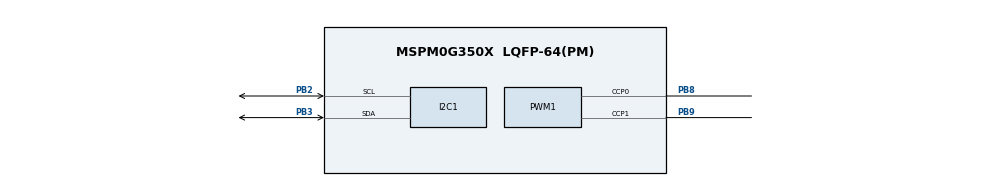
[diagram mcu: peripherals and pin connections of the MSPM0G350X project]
/**
 * @cliArgs --device "MSPM0G350X" --part "Default" --package "LQFP-64(PM)" --product "mspm0_sdk@2.05.00.05"
 * @versions {"tool":"1.24.0+4110"}
 */

/**
 * Import the modules used in this configuration.
 */
const ADC12  = scripting.addModule("/ti/driverlib/ADC12", {}, false);
const ADC121 = ADC12.addInstance();
const GPIO   = scripting.addModule("/ti/driverlib/GPIO", {}, false);
const GPIO1  = GPIO.addInstance();
const GPIO2  = GPIO.addInstance();
const GPIO3  = GPIO.addInstance();
const GPIO4  = GPIO.addInstance();
const GPIO5  = GPIO.addInstance();
const I2C    = scripting.addModule("/ti/driverlib/I2C", {}, false);
const I2C1   = I2C.addInstance();
const PWM    = scripting.addModule("/ti/driverlib/PWM", {}, false);
const PWM1   = PWM.addInstance();
const SYSCTL = scripting.addModule("/ti/driverlib/SYSCTL");
const TIMER  = scripting.addModule("/ti/driverlib/TIMER", {}, false);
const TIMER1 = TIMER.addInstance();

/**
 * Write custom configuration values to the imported modules.
 */
const divider7       = system.clockTree["PLL_PDIV"];
divider7.divideValue = 2;

const divider9       = system.clockTree["UDIV"];
divider9.divideValue = 2;

const multiplier2         = system.clockTree["PLL_QDIV"];
multiplier2.multiplyValue = 5;

const mux8       = system.clockTree["HSCLKMUX"];
mux8.inputSelect = "HSCLKMUX_SYSPLL2X";

ADC121.$name                             = "ADC1";
ADC121.repeatMode                        = true;
ADC121.sampClkDiv                        = "DL_ADC12_CLOCK_DIVIDE_8";
ADC121.adcMem0_name                      = "ADC_Channel0";
ADC121.powerDownMode                     = "DL_ADC12_POWER_DOWN_MODE_MANUAL";
ADC121.adcPin0Config.$name               = "ti_driverlib_gpio_GPIOPinGeneric4";
ADC121.adcPin0Config.hideOutputInversion = scripting.forceWrite(false);

const Board = scripting.addModule("/ti/driverlib/Board", {}, false);

GPIO1.$name                          = "GPIO_motor";
GPIO1.associatedPins.create(5);
GPIO1.associatedPins[0].$name        = "PIN_AIN1";
GPIO1.associatedPins[0].assignedPort = "PORTB";
GPIO1.associatedPins[0].assignedPin  = "6";
GPIO1.associatedPins[1].$name        = "PIN_AIN2";
GPIO1.associatedPins[1].assignedPort = "PORTB";
GPIO1.associatedPins[1].assignedPin  = "7";
GPIO1.associatedPins[2].$name        = "PIN_BIN1";
GPIO1.associatedPins[2].assignedPort = "PORTB";
GPIO1.associatedPins[2].assignedPin  = "15";
GPIO1.associatedPins[3].$name        = "PIN_BIN2";
GPIO1.associatedPins[3].assignedPort = "PORTB";
GPIO1.associatedPins[3].assignedPin  = "0";
GPIO1.associatedPins[4].$name        = "PIN_STBY";
GPIO1.associatedPins[4].assignedPort = "PORTB";
GPIO1.associatedPins[4].assignedPin  = "16";

GPIO2.$name                          = "GPIO_Encoder";
GPIO2.associatedPins.create(4);
GPIO2.associatedPins[0].$name        = "PIN_Left_E1A";
GPIO2.associatedPins[0].direction    = "INPUT";
GPIO2.associatedPins[0].assignedPort = "PORTA";
GPIO2.associatedPins[0].assignedPin  = "12";
GPIO2.associatedPins[0].interruptEn  = true;
GPIO2.associatedPins[0].polarity     = "FALL";
GPIO2.associatedPins[1].$name        = "PIN_Left_E1B";
GPIO2.associatedPins[1].direction    = "INPUT";
GPIO2.associatedPins[1].assignedPin  = "13";
GPIO2.associatedPins[1].assignedPort = "PORTA";
GPIO2.associatedPins[2].$name        = "PIN_Right_E2A";
GPIO2.associatedPins[2].direction    = "INPUT";
GPIO2.associatedPins[2].assignedPort = "PORTB";
GPIO2.associatedPins[2].assignedPin  = "12";
GPIO2.associatedPins[2].interruptEn  = true;
GPIO2.associatedPins[2].polarity     = "FALL";
GPIO2.associatedPins[3].$name        = "PIN_Right_E2B";
GPIO2.associatedPins[3].direction    = "INPUT";
GPIO2.associatedPins[3].assignedPort = "PORTB";
GPIO2.associatedPins[3].assignedPin  = "17";

GPIO3.$name                          = "GPIO_LED";
GPIO3.associatedPins[0].$name        = "PIN_LED";
GPIO3.associatedPins[0].initialValue = "SET";
GPIO3.associatedPins[0].assignedPort = "PORTA";
GPIO3.associatedPins[0].assignedPin  = "0";

GPIO4.$name                              = "GPIO_KEY";
GPIO4.associatedPins.create(8);
GPIO4.associatedPins[0].$name            = "PIN_KEY_ROW1";
GPIO4.associatedPins[0].initialValue     = "SET";
GPIO4.associatedPins[0].assignedPort     = "PORTA";
GPIO4.associatedPins[0].assignedPin      = "26";
GPIO4.associatedPins[1].$name            = "PIN_KEY_ROW2";
GPIO4.associatedPins[1].initialValue     = "SET";
GPIO4.associatedPins[1].assignedPort     = "PORTB";
GPIO4.associatedPins[1].assignedPin      = "18";
GPIO4.associatedPins[2].$name            = "PIN_KEY_ROW3";
GPIO4.associatedPins[2].initialValue     = "SET";
GPIO4.associatedPins[2].assignedPort     = "PORTB";
GPIO4.associatedPins[2].assignedPin      = "24";
GPIO4.associatedPins[3].$name            = "PIN_KEY_ROW4";
GPIO4.associatedPins[3].initialValue     = "SET";
GPIO4.associatedPins[3].assignedPort     = "PORTA";
GPIO4.associatedPins[3].assignedPin      = "24";
GPIO4.associatedPins[4].$name            = "PIN_KEY_COL1";
GPIO4.associatedPins[4].direction        = "INPUT";
GPIO4.associatedPins[4].assignedPort     = "PORTA";
GPIO4.associatedPins[4].assignedPin      = "22";
GPIO4.associatedPins[4].internalResistor = "PULL_UP";
GPIO4.associatedPins[5].$name            = "PIN_KEY_COL2";
GPIO4.associatedPins[5].direction        = "INPUT";
GPIO4.associatedPins[5].internalResistor = "PULL_UP";
GPIO4.associatedPins[5].assignedPort     = "PORTA";
GPIO4.associatedPins[5].assignedPin      = "8";
GPIO4.associatedPins[6].$name            = "PIN_KEY_COL3";
GPIO4.associatedPins[6].direction        = "INPUT";
GPIO4.associatedPins[6].assignedPort     = "PORTB";
GPIO4.associatedPins[6].assignedPin      = "19";
GPIO4.associatedPins[6].internalResistor = "PULL_UP";
GPIO4.associatedPins[7].$name            = "PIN_KEY_COL4";
GPIO4.associatedPins[7].direction        = "INPUT";
GPIO4.associatedPins[7].assignedPort     = "PORTA";
GPIO4.associatedPins[7].assignedPin      = "25";
GPIO4.associatedPins[7].internalResistor = "PULL_UP";

GPIO5.$name                   = "Gray_Address";
GPIO5.port                    = "PORTB";
GPIO5.associatedPins.create(3);
GPIO5.associatedPins[0].$name = "PIN_0";
GPIO5.associatedPins[1].$name = "PIN_1";
GPIO5.associatedPins[2].$name = "PIN_2";

I2C1.$name                             = "I2C_OLED";
I2C1.basicEnableController             = true;
I2C1.basicControllerStandardBusSpeed   = "Fast";
I2C1.peripheral.$assign                = "I2C1";
I2C1.peripheral.sdaPin.$assign         = "PB3";
I2C1.peripheral.sclPin.$assign         = "PB2";
I2C1.sdaPinConfig.$name                = "ti_driverlib_gpio_GPIOPinGeneric0";
I2C1.sdaPinConfig.hideOutputInversion  = scripting.forceWrite(false);
I2C1.sdaPinConfig.onlyInternalResistor = scripting.forceWrite(false);
I2C1.sdaPinConfig.passedPeripheralType = scripting.forceWrite("Digital");
I2C1.sclPinConfig.$name                = "ti_driverlib_gpio_GPIOPinGeneric1";
I2C1.sclPinConfig.hideOutputInversion  = scripting.forceWrite(false);
I2C1.sclPinConfig.onlyInternalResistor = scripting.forceWrite(false);
I2C1.sclPinConfig.passedPeripheralType = scripting.forceWrite("Digital");

PWM1.$name                      = "PWM_0";
PWM1.timerCount                 = 800;
PWM1.clockPrescale              = 100;
PWM1.peripheral.$assign         = "TIMA0";
PWM1.peripheral.ccp0Pin.$assign = "PB8";
PWM1.peripheral.ccp1Pin.$assign = "PB9";
PWM1.PWM_CHANNEL_0.$name        = "ti_driverlib_pwm_PWMTimerCC0";
PWM1.PWM_CHANNEL_1.$name        = "ti_driverlib_pwm_PWMTimerCC1";
PWM1.ccp0PinConfig.$name        = "ti_driverlib_gpio_GPIOPinGeneric2";
PWM1.ccp1PinConfig.$name        = "ti_driverlib_gpio_GPIOPinGeneric3";

SYSCTL.forceDefaultClkConfig = true;
SYSCTL.clockTreeEn           = true;
scripting.suppress("For best practices when the CPUCLK is running at 32MHz and above, clear the flash status bit using DL_FlashCTL_executeClearStatus\\(\\) before executing any flash operation\\. Otherwise there may be false positives\\.", SYSCTL);

TIMER1.$name              = "TIMER_speedget";
TIMER1.timerMode          = "PERIODIC";
TIMER1.timerPeriod        = "50 ms";
TIMER1.timerClkPrescale   = 100;
TIMER1.interrupts         = ["ZERO"];
TIMER1.peripheral.$assign = "TIMG0";

/**
 * Pinmux solution for unlocked pins/peripherals. This ensures that minor changes to the automatic solver in a future
 * version of the tool will not impact the pinmux you originally saw.  These lines can be completely deleted in order to
 * re-solve from scratch.
 */
ADC121.peripheral.$suggestSolution           = "ADC0";
ADC121.peripheral.adcPin0.$suggestSolution   = "PA27";
Board.peripheral.$suggestSolution            = "DEBUGSS";
Board.peripheral.swclkPin.$suggestSolution   = "PA20";
Board.peripheral.swdioPin.$suggestSolution   = "PA19";
GPIO1.associatedPins[0].pin.$suggestSolution = "PB6";
GPIO1.associatedPins[1].pin.$suggestSolution = "PB7";
GPIO1.associatedPins[2].pin.$suggestSolution = "PB15";
GPIO1.associatedPins[3].pin.$suggestSolution = "PB0";
GPIO1.associatedPins[4].pin.$suggestSolution = "PB16";
GPIO2.associatedPins[0].pin.$suggestSolution = "PA12";
GPIO2.associatedPins[1].pin.$suggestSolution = "PA13";
GPIO2.associatedPins[2].pin.$suggestSolution = "PB12";
GPIO2.associatedPins[3].pin.$suggestSolution = "PB17";
GPIO3.associatedPins[0].pin.$suggestSolution = "PA0";
GPIO4.associatedPins[0].pin.$suggestSolution = "PA26";
GPIO4.associatedPins[1].pin.$suggestSolution = "PB18";
GPIO4.associatedPins[2].pin.$suggestSolution = "PB24";
GPIO4.associatedPins[3].pin.$suggestSolution = "PA24";
GPIO4.associatedPins[4].pin.$suggestSolution = "PA22";
GPIO4.associatedPins[5].pin.$suggestSolution = "PA8";
GPIO4.associatedPins[6].pin.$suggestSolution = "PB19";
GPIO4.associatedPins[7].pin.$suggestSolution = "PA25";
GPIO5.associatedPins[0].pin.$suggestSolution = "PB20";
GPIO5.associatedPins[1].pin.$suggestSolution = "PB14";
GPIO5.associatedPins[2].pin.$suggestSolution = "PB13";
